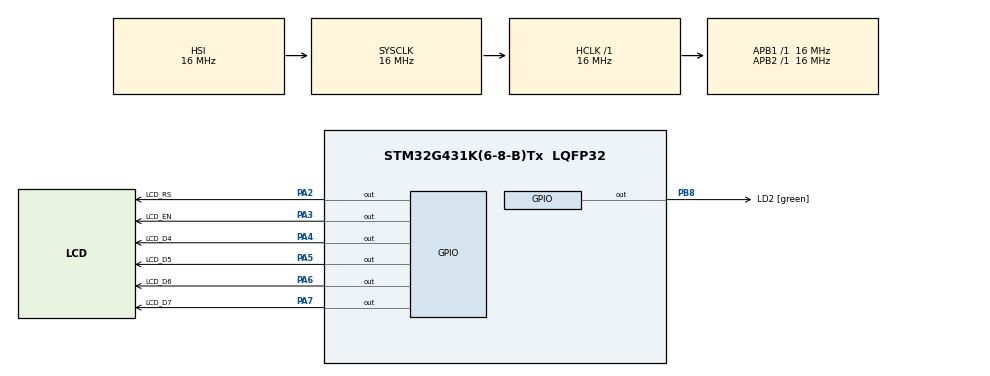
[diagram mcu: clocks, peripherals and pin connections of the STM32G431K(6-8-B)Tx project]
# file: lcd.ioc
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Mcu.Family=STM32G4
Mcu.Name=STM32G431K(6-8-B)Tx
Mcu.Package=LQFP32
NVIC.PriorityGroup=NVIC_PRIORITYGROUP_4
PA13.GPIO_Label=T_SWDIO
PA13.Mode=Serial_Wire
PA13.Signal=SYS_JTMS-SWDIO
PA14.GPIO_Label=T_SWCLK
PA14.Mode=Serial_Wire
PA14.Signal=SYS_JTCK-SWCLK
PA2.GPIO_Label=LCD_RS
PA2.Signal=GPIO_Output
PA3.GPIO_Label=LCD_EN
PA3.Signal=GPIO_Output
PA4.GPIO_Label=LCD_D4
PA4.Signal=GPIO_Output
PA5.GPIO_Label=LCD_D5
PA5.Signal=GPIO_Output
PA6.GPIO_Label=LCD_D6
PA6.Signal=GPIO_Output
PA7.GPIO_Label=LCD_D7
PA7.Signal=GPIO_Output
PB3.GPIO_Label=T_SWO
PB3.Signal=SYS_JTDO-SWO
PB8-BOOT0.GPIO_Label=LD2 [green]
PB8-BOOT0.Signal=GPIO_Output
ProjectManager.HeapSize=0x200
ProjectManager.StackSize=0x400
ProjectManager.TargetToolchain=STM32CubeIDE
RCC.ADC12Freq_Value=16000000
RCC.AHBFreq_Value=16000000
RCC.APB1Freq_Value=16000000
RCC.APB1TimFreq_Value=16000000
RCC.APB2Freq_Value=16000000
RCC.APB2TimFreq_Value=16000000
RCC.CortexFreq_Value=16000000
RCC.EXTERNAL_CLOCK_VALUE=12288000
RCC.HCLKFreq_Value=16000000
RCC.HSE_VALUE=8000000
RCC.HSI48_VALUE=48000000
RCC.HSI_VALUE=16000000
RCC.LSE_VALUE=32768
RCC.PLLM=RCC_PLLM_DIV4
RCC.PLLN=85
RCC.SYSCLKFreq_VALUE=16000000
RCC.USBFreq_Value=170000000
RCC.VCOOutputFreq_Value=340000000
board=NUCLEO-G431KB

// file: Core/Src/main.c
/* USER CODE BEGIN Header */
/**
  ******************************************************************************
  * @file           : main.c
  * @brief          : Main program body
  ******************************************************************************
  * @attention
  *
  * Copyright (c) 2022 STMicroelectronics.
  * All rights reserved.
  *
  * This software is licensed under terms that can be found in the LICENSE file
  * in the root directory of this software component.
  * If no LICENSE file comes with this software, it is provided AS-IS.
  *
  ******************************************************************************
  */
/* USER CODE END Header */
#include "main.h"

void SystemClock_Config(void);
static void MX_GPIO_Init(void);
/* USER CODE BEGIN PFP */
#include "LCD.h"
/* USER CODE END PFP */

int main(void)
{

  /* MCU Configuration--------------------------------------------------------*/

  /* Reset of all peripherals, Initializes the Flash interface and the Systick. */
  HAL_Init();

  /* Configure the system clock */
  SystemClock_Config();

  /* Initialize all configured peripherals */
  MX_GPIO_Init();
  /* USER CODE BEGIN 2 */
  lcd_init(_LCD_4BIT, _LCD_FONT_5x8, _LCD_2LINE);
  lcd_print(2, 2, "hello world");
  /* USER CODE END 2 */

  /* Infinite loop */
  while (1)
  {

  }
}

void SystemClock_Config(void)
{
  RCC_OscInitTypeDef RCC_OscInitStruct = {0};
  RCC_ClkInitTypeDef RCC_ClkInitStruct = {0};

  /** Configure the main internal regulator output voltage
  */
  HAL_PWREx_ControlVoltageScaling(PWR_REGULATOR_VOLTAGE_SCALE1);

  /** Initializes the RCC Oscillators according to the specified parameters
  * in the RCC_OscInitTypeDef structure.
  */
  RCC_OscInitStruct.OscillatorType = RCC_OSCILLATORTYPE_HSI;
  RCC_OscInitStruct.HSIState = RCC_HSI_ON;
  RCC_OscInitStruct.HSICalibrationValue = RCC_HSICALIBRATION_DEFAULT;
  RCC_OscInitStruct.PLL.PLLState = RCC_PLL_NONE;
  if (HAL_RCC_OscConfig(&RCC_OscInitStruct) != HAL_OK)
  {
    Error_Handler();
  }

  /** Initializes the CPU, AHB and APB buses clocks
  */
  RCC_ClkInitStruct.ClockType = RCC_CLOCKTYPE_HCLK|RCC_CLOCKTYPE_SYSCLK
                              |RCC_CLOCKTYPE_PCLK1|RCC_CLOCKTYPE_PCLK2;
  RCC_ClkInitStruct.SYSCLKSource = RCC_SYSCLKSOURCE_HSI;
  RCC_ClkInitStruct.AHBCLKDivider = RCC_SYSCLK_DIV1;
  RCC_ClkInitStruct.APB1CLKDivider = RCC_HCLK_DIV1;
  RCC_ClkInitStruct.APB2CLKDivider = RCC_HCLK_DIV1;

  if (HAL_RCC_ClockConfig(&RCC_ClkInitStruct, FLASH_LATENCY_0) != HAL_OK)
  {
    Error_Handler();
  }
}

static void MX_GPIO_Init(void)
{
  GPIO_InitTypeDef GPIO_InitStruct = {0};

  /* GPIO Ports Clock Enable */
  __HAL_RCC_GPIOA_CLK_ENABLE();
  __HAL_RCC_GPIOB_CLK_ENABLE();

  /*Configure GPIO pin Output Level */
  HAL_GPIO_WritePin(GPIOA, LCD_RS_Pin|LCD_EN_Pin|LCD_D4_Pin|LCD_D5_Pin
                          |LCD_D6_Pin|LCD_D7_Pin, GPIO_PIN_RESET);

  /*Configure GPIO pin Output Level */
  HAL_GPIO_WritePin(LD2_GPIO_Port, LD2_Pin, GPIO_PIN_RESET);

  /*Configure GPIO pins : LCD_RS_Pin LCD_EN_Pin LCD_D4_Pin LCD_D5_Pin
                           LCD_D6_Pin LCD_D7_Pin */
  GPIO_InitStruct.Pin = LCD_RS_Pin|LCD_EN_Pin|LCD_D4_Pin|LCD_D5_Pin
                          |LCD_D6_Pin|LCD_D7_Pin;
  GPIO_InitStruct.Mode = GPIO_MODE_OUTPUT_PP;
  GPIO_InitStruct.Pull = GPIO_NOPULL;
  GPIO_InitStruct.Speed = GPIO_SPEED_FREQ_LOW;
  HAL_GPIO_Init(GPIOA, &GPIO_InitStruct);

  /*Configure GPIO pin : LD2_Pin */
  GPIO_InitStruct.Pin = LD2_Pin;
  GPIO_InitStruct.Mode = GPIO_MODE_OUTPUT_PP;
  GPIO_InitStruct.Pull = GPIO_NOPULL;
  GPIO_InitStruct.Speed = GPIO_SPEED_FREQ_LOW;
  HAL_GPIO_Init(LD2_GPIO_Port, &GPIO_InitStruct);

}

void Error_Handler(void)
{
  __disable_irq();
  while (1)
  {
  }
}
